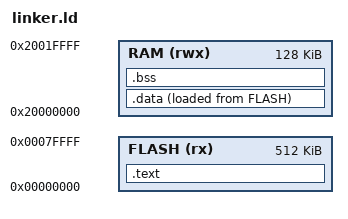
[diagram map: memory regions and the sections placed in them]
ENTRY(Reset_Handler)

MEMORY
{
    FLASH (rx)  : ORIGIN = 0x00000000, LENGTH = 512K
    RAM   (rwx) : ORIGIN = 0x20000000, LENGTH = 128K
}

SECTIONS
{
    .text :
    {
        KEEP(*(.isr_vector))
        *(.text*)
        *(.rodata*)
    } > FLASH

    .data :
    {
        *(.data*)
    } > RAM AT > FLASH

    .bss :
    {
        __bss_start__ = .;
        *(.bss*)
        *(COMMON)
        __bss_end__ = .;
    } > RAM

    __StackTop = ORIGIN(RAM) + LENGTH(RAM);
    __StackLimit = __StackTop - 2048;

    /DISCARD/ :
    {
        *(.ARM.exidx*)
        *(.ARM.attributes*)
    }
}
